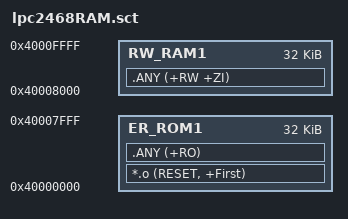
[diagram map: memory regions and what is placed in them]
LR_ROM1 0x40000000 0x10000  {    ; load region size_region
  ER_ROM1 0x40000000 0x8000  {  ; load address = execution address
   *.o (RESET, +First)
   .ANY (+RO)
  }
  RW_RAM1 0x40008000 0x8000  {  ; RW data
   .ANY (+RW +ZI)
  }
}
